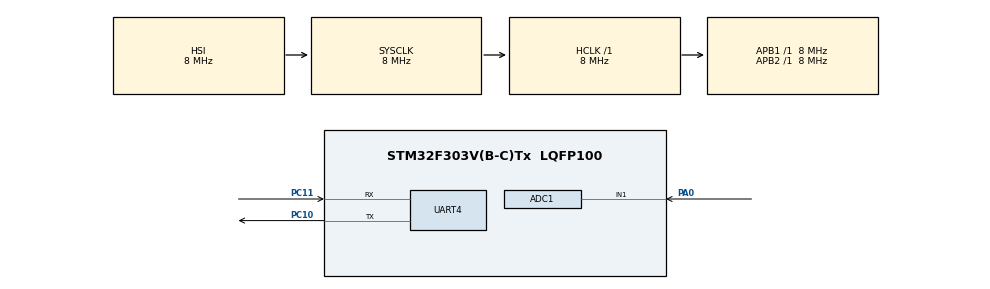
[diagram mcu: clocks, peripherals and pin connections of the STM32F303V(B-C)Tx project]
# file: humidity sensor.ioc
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ADC1.Channel-1\#ChannelRegularConversion=ADC_CHANNEL_1
ADC1.ContinuousConvMode=ENABLE
ADC1.NbrOfConversionFlag=1
ADC1.Offset-1\#ChannelRegularConversion=0
ADC1.OffsetNumber-1\#ChannelRegularConversion=ADC_OFFSET_NONE
ADC1.Rank-1\#ChannelRegularConversion=1
ADC1.SamplingTime-1\#ChannelRegularConversion=ADC_SAMPLETIME_1CYCLE_5
ADC1.master=1
Mcu.Family=STM32F3
Mcu.Name=STM32F303V(B-C)Tx
Mcu.Package=LQFP100
NVIC.PriorityGroup=NVIC_PRIORITYGROUP_4
PA0.Mode=IN1-Single-Ended
PA0.Signal=ADC1_IN1
PC10.Mode=Asynchronous
PC10.Signal=UART4_TX
PC11.Mode=Asynchronous
PC11.Signal=UART4_RX
PC14-OSC32_IN.Mode=LSE-External-Oscillator
PC14-OSC32_IN.Signal=RCC_OSC32_IN
PC15-OSC32_OUT.Mode=LSE-External-Oscillator
PC15-OSC32_OUT.Signal=RCC_OSC32_OUT
PF0-OSC_IN.Mode=HSE-External-Oscillator
PF0-OSC_IN.Signal=RCC_OSC_IN
PF1-OSC_OUT.Mode=HSE-External-Oscillator
PF1-OSC_OUT.Signal=RCC_OSC_OUT
ProjectManager.HeapSize=0x200
ProjectManager.StackSize=0x400
ProjectManager.TargetToolchain=MDK-ARM V5
RCC.AHBFreq_Value=8000000
RCC.APB1Freq_Value=8000000
RCC.APB2Freq_Value=8000000
RCC.CortexFreq_Value=8000000
RCC.HSE_VALUE=8000000
RCC.HSI_VALUE=8000000
RCC.PLLMUL=RCC_PLL_MUL4
RCC.SYSCLKFreq_VALUE=8000000
RCC.USBFreq_Value=16000000
board=custom

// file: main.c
/* USER CODE BEGIN Header */
/**
  ******************************************************************************
  * @file           : main.c
  * @brief          : Main program body
  ******************************************************************************
  * @attention
  *
  * <h2><center>&copy; Copyright (c) 2019 STMicroelectronics.
  * All rights reserved.</center></h2>
  *
  * This software component is licensed by ST under BSD 3-Clause license,
  * the "License"; You may not use this file except in compliance with the
  * License. You may obtain a copy of the License at:
  *                        opensource.org/licenses/BSD-3-Clause
  *
  ******************************************************************************
  */
/* USER CODE END Header */

#include "main.h"

ADC_HandleTypeDef hadc1;

UART_HandleTypeDef huart4;

void SystemClock_Config(void);
static void MX_GPIO_Init(void);
static void MX_ADC1_Init(void);
static void MX_UART4_Init(void);

int main(void)
{

  /* MCU Configuration--------------------------------------------------------*/

  /* Reset of all peripherals, Initializes the Flash interface and the Systick. */
  HAL_Init();

  /* Configure the system clock */
  SystemClock_Config();

  /* Initialize all configured peripherals */
  MX_GPIO_Init();
  MX_ADC1_Init();
  MX_UART4_Init();
  /* USER CODE BEGIN 2 */
uint32_t sensorValue=0;
  /* USER CODE END 2 */

  /* Infinite loop */
  /* USER CODE BEGIN WHILE */
  while (1)
  {
		HAL_UART_Transmit(&huart4,sensorValue,4,100);
		HAL_ADC_Start(&hadc1);
    HAL_ADC_PollForConversion(&hadc1, 100);
		sensorValue = HAL_ADC_GetValue(&hadc1);
    HAL_ADC_Stop(&hadc1);

    /* USER CODE END WHILE */

  }
}

void SystemClock_Config(void)
{
  RCC_OscInitTypeDef RCC_OscInitStruct = {0};
  RCC_ClkInitTypeDef RCC_ClkInitStruct = {0};
  RCC_PeriphCLKInitTypeDef PeriphClkInit = {0};

  /** Initializes the CPU, AHB and APB busses clocks
  */
  RCC_OscInitStruct.OscillatorType = RCC_OSCILLATORTYPE_HSI;
  RCC_OscInitStruct.HSIState = RCC_HSI_ON;
  RCC_OscInitStruct.HSICalibrationValue = RCC_HSICALIBRATION_DEFAULT;
  RCC_OscInitStruct.PLL.PLLState = RCC_PLL_ON;
  RCC_OscInitStruct.PLL.PLLSource = RCC_PLLSOURCE_HSI;
  RCC_OscInitStruct.PLL.PLLMUL = RCC_PLL_MUL4;
  if (HAL_RCC_OscConfig(&RCC_OscInitStruct) != HAL_OK)
  {
    Error_Handler();
  }
  /** Initializes the CPU, AHB and APB busses clocks
  */
  RCC_ClkInitStruct.ClockType = RCC_CLOCKTYPE_HCLK|RCC_CLOCKTYPE_SYSCLK
                              |RCC_CLOCKTYPE_PCLK1|RCC_CLOCKTYPE_PCLK2;
  RCC_ClkInitStruct.SYSCLKSource = RCC_SYSCLKSOURCE_HSI;
  RCC_ClkInitStruct.AHBCLKDivider = RCC_SYSCLK_DIV1;
  RCC_ClkInitStruct.APB1CLKDivider = RCC_HCLK_DIV1;
  RCC_ClkInitStruct.APB2CLKDivider = RCC_HCLK_DIV1;

  if (HAL_RCC_ClockConfig(&RCC_ClkInitStruct, FLASH_LATENCY_0) != HAL_OK)
  {
    Error_Handler();
  }
  PeriphClkInit.PeriphClockSelection = RCC_PERIPHCLK_UART4|RCC_PERIPHCLK_ADC12;
  PeriphClkInit.Uart4ClockSelection = RCC_UART4CLKSOURCE_PCLK1;
  PeriphClkInit.Adc12ClockSelection = RCC_ADC12PLLCLK_DIV1;
  if (HAL_RCCEx_PeriphCLKConfig(&PeriphClkInit) != HAL_OK)
  {
    Error_Handler();
  }
}

static void MX_ADC1_Init(void)
{

  ADC_MultiModeTypeDef multimode = {0};
  ADC_ChannelConfTypeDef sConfig = {0};

  /** Common config
  */
  hadc1.Instance = ADC1;
  hadc1.Init.ClockPrescaler = ADC_CLOCK_ASYNC_DIV1;
  hadc1.Init.Resolution = ADC_RESOLUTION_12B;
  hadc1.Init.ScanConvMode = ADC_SCAN_DISABLE;
  hadc1.Init.ContinuousConvMode = ENABLE;
  hadc1.Init.DiscontinuousConvMode = DISABLE;
  hadc1.Init.ExternalTrigConvEdge = ADC_EXTERNALTRIGCONVEDGE_NONE;
  hadc1.Init.ExternalTrigConv = ADC_SOFTWARE_START;
  hadc1.Init.DataAlign = ADC_DATAALIGN_RIGHT;
  hadc1.Init.NbrOfConversion = 1;
  hadc1.Init.DMAContinuousRequests = DISABLE;
  hadc1.Init.EOCSelection = ADC_EOC_SINGLE_CONV;
  hadc1.Init.LowPowerAutoWait = DISABLE;
  hadc1.Init.Overrun = ADC_OVR_DATA_OVERWRITTEN;
  if (HAL_ADC_Init(&hadc1) != HAL_OK)
  {
    Error_Handler();
  }
  /** Configure the ADC multi-mode
  */
  multimode.Mode = ADC_MODE_INDEPENDENT;
  if (HAL_ADCEx_MultiModeConfigChannel(&hadc1, &multimode) != HAL_OK)
  {
    Error_Handler();
  }
  /** Configure Regular Channel
  */
  sConfig.Channel = ADC_CHANNEL_1;
  sConfig.Rank = ADC_REGULAR_RANK_1;
  sConfig.SingleDiff = ADC_SINGLE_ENDED;
  sConfig.SamplingTime = ADC_SAMPLETIME_1CYCLE_5;
  sConfig.OffsetNumber = ADC_OFFSET_NONE;
  sConfig.Offset = 0;
  if (HAL_ADC_ConfigChannel(&hadc1, &sConfig) != HAL_OK)
  {
    Error_Handler();
  }

}

static void MX_UART4_Init(void)
{

  huart4.Instance = UART4;
  huart4.Init.BaudRate = 115200;
  huart4.Init.WordLength = UART_WORDLENGTH_8B;
  huart4.Init.StopBits = UART_STOPBITS_1;
  huart4.Init.Parity = UART_PARITY_NONE;
  huart4.Init.Mode = UART_MODE_TX_RX;
  huart4.Init.HwFlowCtl = UART_HWCONTROL_NONE;
  huart4.Init.OverSampling = UART_OVERSAMPLING_16;
  huart4.Init.OneBitSampling = UART_ONE_BIT_SAMPLE_DISABLE;
  huart4.AdvancedInit.AdvFeatureInit = UART_ADVFEATURE_NO_INIT;
  if (HAL_UART_Init(&huart4) != HAL_OK)
  {
    Error_Handler();
  }

}

static void MX_GPIO_Init(void)
{

  /* GPIO Ports Clock Enable */
  __HAL_RCC_GPIOC_CLK_ENABLE();
  __HAL_RCC_GPIOF_CLK_ENABLE();
  __HAL_RCC_GPIOA_CLK_ENABLE();

}

void Error_Handler(void)
{
}

/************************ (C) COPYRIGHT STMicroelectronics *****END OF FILE****/
